# ATmega64C1 register map
Vendor: Atmel; File version: 1.0
CPU: other r0p0, little endian, no MPU, no FPU, 4 interrupt priority bits
Registers are 8-bit, read-write, reset 0x0 unless marked. A register's access mark holds for its fields unless they carry their own. Offsets are from the block's base; [hi:lo] are bit positions; {n}, {i} and the like mark numbered series.

## CPU — CPU Registers
Base 0x00000039
0x00 GPIOR1 — General Purpose IO Register 1
  [7:0] GPIOR — General Purpose IO Register 1 bis
0x01 GPIOR2 — General Purpose IO Register 2
  [7:0] GPIOR — General Purpose IO Register 2 bis
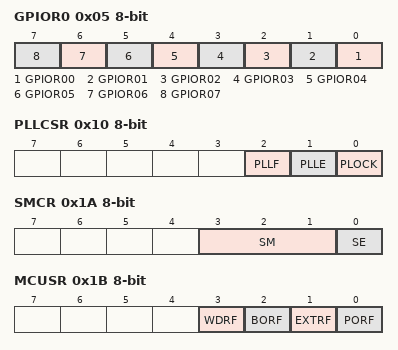
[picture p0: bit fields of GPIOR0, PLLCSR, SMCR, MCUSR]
0x05 GPIOR0 — General Purpose IO Register 0
  [n] GPIOR{n:02} (n=0..7) — General Purpose IO Register 0 bit {n}
0x10 PLLCSR — PLL Control And Status Register
  [2] PLLF — PLL Factor
  [1] PLLE — PLL Enable
  [0] PLOCK — PLL Lock Detector
0x1A SMCR — Sleep Mode Control Register
  [3:1] SM — Sleep Mode Select bits
    0=IDLE; 1=ADC (ADC Noise Reduction (If Available)); 2=PDOWN (Power Down); 6=STDBY (Standby)
  [0] SE — Sleep Enable
0x1B MCUSR — MCU Status Register
  [3] WDRF — Watchdog Reset Flag
  [2] BORF — Brown-out Reset Flag
  [1] EXTRF — External Reset Flag
  [0] PORF — Power-on reset flag
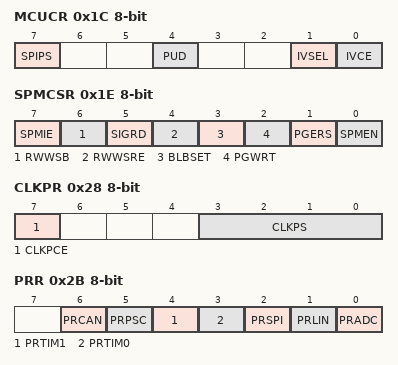
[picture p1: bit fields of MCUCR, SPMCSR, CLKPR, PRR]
0x1C MCUCR — MCU Control Register
  [7] SPIPS — SPI Pin Select
  [4] PUD — Pull-up disable
  [1] IVSEL — Interrupt Vector Select
  [0] IVCE — Interrupt Vector Change Enable
0x1E SPMCSR — Store Program Memory Control Register
  [7] SPMIE — SPM Interrupt Enable
  [6] RWWSB — Read While Write Section Busy
  [5] SIGRD — Signature Row Read
  [4] RWWSRE — Read While Write section read enable
  [3] BLBSET — Boot Lock Bit Set
  [2] PGWRT — Page Write
  [1] PGERS — Page Erase
  [0] SPMEN — Store Program Memory Enable
0x28 CLKPR
  [7] CLKPCE
  [3:0] CLKPS
    0=1; 1=2; 2=4; 3=8; 4=16; 5=32; 6=64; 7=128; 8=256
0x2B PRR — Power Reduction Register
  [6] PRCAN — Power Reduction CAN
  [5] PRPSC — Power Reduction PSC
  [4] PRTIM1 — Power Reduction Timer/Counter1
  [3] PRTIM0 — Power Reduction Timer/Counter0
  [2] PRSPI — Power Reduction Serial Peripheral Interface
  [1] PRLIN — Power Reduction LIN UART
  [0] PRADC — Power Reduction ADC
0x2D OSCCAL — Oscillator Calibration Value
  [7:0] OSCCAL — Oscillator Calibration

## DAC — Digital-to-Analog Converter
Base 0x00000090
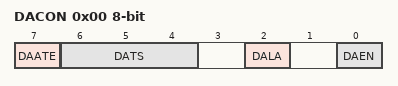
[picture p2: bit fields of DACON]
0x00 DACON — DAC Control Register
  [7] DAATE — DAC Auto Trigger Enable Bit
  [6:4] DATS — DAC Trigger Selection Bits
    0=ANALOG_COMPARATOR_0; 1=ANALOG_COMPARATOR_1; 2=EXTERNAL_INTERRUPT_REQUEST_0; 3=TIMER_COUNTER0_COMPARE_MATCH_A; 4=TIMER_COUNTER0_OVERFLOW; 5=TIMER_COUNTER1_COMPARE_MATCH_B; 6=TIMER_COUNTER1_OVERFLOW; 7=TIMER_COUNTER1_CAPTURE_EVENT
  [2] DALA — DAC Left Adjust
  [0] DAEN — DAC Enable Bit
0x01 DACL — DAC Data Register Low Byte
  [7:0] DACL — DAC Data Register Low Byte Bits
0x02 DACH — DAC Data Register High Byte
  [7:0] DACH — DAC Data Register High Byte Bits

## EEPROM
Base 0x0000003F
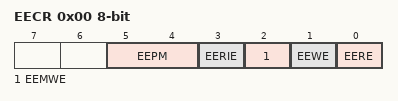
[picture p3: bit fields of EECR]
0x00 EECR — EEPROM Control Register
  [5:4] EEPM
    0=ERASE_AND_WRITE_IN_ONE_OPERATION; 1=ERASE_ONLY; 2=WRITE_ONLY
  [3] EERIE — EEProm Ready Interrupt Enable
  [2] EEMWE — EEPROM Master Write Enable
  [1] EEWE — EEPROM Write Enable
  [0] EERE — EEPROM Read Enable
0x01 EEDR — EEPROM Data Register
0x02 EEAR 16-bit (reset mask 0xFF) — EEPROM Read/Write Access

## EXINT — External Interrupts
Base 0x0000003B
0x00 PCIFR — Pin Change Interrupt Flag Register
  [3:0] PCIF — Pin Change Interrupt Flags
0x01 EIFR — External Interrupt Flag Register
  [3:0] INTF — External Interrupt Flags
0x02 EIMSK — External Interrupt Mask Register
  [3:0] INT — External Interrupt Request 3 Enable
0x2D PCICR — Pin Change Interrupt Control Register
  [3:0] PCIE — Pin Change Interrupt Enables
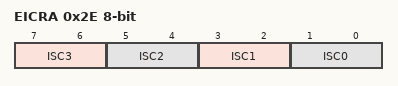
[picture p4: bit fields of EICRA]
0x2E EICRA — External Interrupt Control Register
  [all] fields
    0=LOW_LEVEL_OF_INTX; 1=ANY_LOGICAL_CHANGE_OF_INTX; 2=FALLING_EDGE_OF_INTX; 3=RISING_EDGE_OF_INTX
  [7:6] ISC3 — External Interrupt Sense Control Bit
  [5:4] ISC2 — External Interrupt Sense Control Bit
  [3:2] ISC1 — External Interrupt Sense Control 1 Bits
  [1:0] ISC0 — External Interrupt Sense Control 0 Bits
{0x2F+i} PCMSK{i} (i=0..2) — Pin Change Mask Register {i}
  [7:0] PCINT — Pin Change Enable Masks
0x32 PCMSK3 — Pin Change Mask Register 3
  [2:0] PCINT — Pin Change Enable Masks
